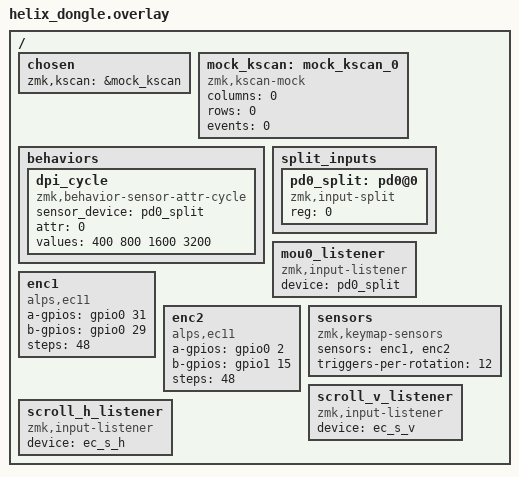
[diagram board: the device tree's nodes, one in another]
#include "helix.dtsi"
#include <zephyr/dt-bindings/input/input-event-codes.h>

/ {
    chosen {
        zmk,kscan = &mock_kscan;
    };

    mock_kscan: mock_kscan_0 {
        compatible = "zmk,kscan-mock";
        columns = <0>;
        rows = <0>;
        events = <0>;
    };

    behaviors {
        dpi_cycle: dpi_cycle {
            compatible = "zmk,behavior-sensor-attr-cycle";
            #binding-cells = <1>;
            sensor_device = <&pd0_split>;
            attr = <0>; /* PAW3395_ATTR_CPI forwarded via split */
            values = <400 800 1600 3200>;
        };
    };

    split_inputs {
        #address-cells = <1>;
        #size-cells = <0>;

        pd0_split: pd0@0 {
            compatible = "zmk,input-split";
            reg = <0>;
        };
    };

    mou0_listener: mou0_listener {
        compatible = "zmk,input-listener";
        device = <&pd0_split>;
    };

    /* Encoder stubs — GPIOs are unconnected on the dongle; pull-ups keep them
     * quiet. These nodes exist solely so ZMK_KEYMAP_SENSORS_LEN=2, which
     * prevents an out-of-bounds access in behavior_sensor_rotate_common when
     * forwarded sensor events from the peripheral arrive here. */
    enc1: enc1 {
        compatible = "alps,ec11";
        status = "okay";
        a-gpios = <&gpio0 31 (GPIO_ACTIVE_HIGH | GPIO_PULL_UP)>;
        b-gpios = <&gpio0 29 (GPIO_ACTIVE_HIGH | GPIO_PULL_UP)>;
        steps = <48>;
    };

    enc2: enc2 {
        compatible = "alps,ec11";
        status = "okay";
        a-gpios = <&gpio0 2  (GPIO_ACTIVE_HIGH | GPIO_PULL_UP)>;
        b-gpios = <&gpio1 15 (GPIO_ACTIVE_HIGH | GPIO_PULL_UP)>;
        steps = <48>;
    };

    sensors: sensors {
        compatible = "zmk,keymap-sensors";
        sensors = <&enc1 &enc2>;
        triggers-per-rotation = <12>;
    };

    /* Listeners for scroll events generated by ec_s_v / ec_s_h behaviors
     * when the dongle processes forwarded encoder sensor events. */
    scroll_v_listener: scroll_v_listener {
        compatible = "zmk,input-listener";
        device = <&ec_s_v>;
    };

    scroll_h_listener: scroll_h_listener {
        compatible = "zmk,input-listener";
        device = <&ec_s_h>;
    };
};
